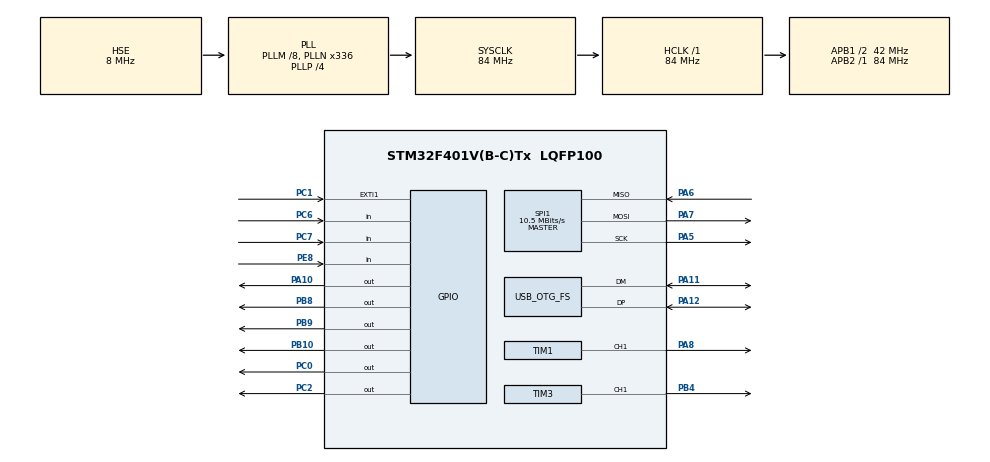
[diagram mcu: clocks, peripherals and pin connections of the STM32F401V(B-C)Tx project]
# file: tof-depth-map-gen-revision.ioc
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Dma.Request0=SPI1_RX
Dma.Request1=SPI1_TX
Dma.SPI1_RX.0.Direction=DMA_PERIPH_TO_MEMORY
Dma.SPI1_RX.0.FIFOMode=DMA_FIFOMODE_DISABLE
Dma.SPI1_RX.0.Instance=DMA2_Stream2
Dma.SPI1_RX.0.MemDataAlignment=DMA_MDATAALIGN_BYTE
Dma.SPI1_RX.0.MemInc=DMA_MINC_ENABLE
Dma.SPI1_RX.0.Mode=DMA_NORMAL
Dma.SPI1_RX.0.PeriphDataAlignment=DMA_PDATAALIGN_BYTE
Dma.SPI1_RX.0.PeriphInc=DMA_PINC_DISABLE
Dma.SPI1_RX.0.Priority=DMA_PRIORITY_LOW
Dma.SPI1_TX.1.Direction=DMA_MEMORY_TO_PERIPH
Dma.SPI1_TX.1.FIFOMode=DMA_FIFOMODE_DISABLE
Dma.SPI1_TX.1.Instance=DMA2_Stream3
Dma.SPI1_TX.1.MemDataAlignment=DMA_MDATAALIGN_BYTE
Dma.SPI1_TX.1.MemInc=DMA_MINC_ENABLE
Dma.SPI1_TX.1.Mode=DMA_NORMAL
Dma.SPI1_TX.1.PeriphDataAlignment=DMA_PDATAALIGN_BYTE
Dma.SPI1_TX.1.PeriphInc=DMA_PINC_DISABLE
Dma.SPI1_TX.1.Priority=DMA_PRIORITY_LOW
Mcu.Family=STM32F4
Mcu.Name=STM32F401V(B-C)Tx
Mcu.Package=LQFP100
NVIC.DMA2_Stream2_IRQn=true\:1\:1\:true\:false\:true\:false\:true
NVIC.DMA2_Stream3_IRQn=true\:1\:1\:true\:false\:true\:false\:true
NVIC.EXTI1_IRQn=true\:1\:3\:true\:false\:true\:true\:true
NVIC.OTG_FS_IRQn=true\:1\:5\:true\:false\:true\:true\:true
NVIC.PriorityGroup=NVIC_PRIORITYGROUP_1
NVIC.TIM2_IRQn=true\:1\:0\:true\:false\:true\:true\:true
PA10.Signal=GPIO_Output
PA11.Mode=Device_Only
PA11.Signal=USB_OTG_FS_DM
PA12.Mode=Device_Only
PA12.Signal=USB_OTG_FS_DP
PA5.Mode=Full_Duplex_Master
PA5.Signal=SPI1_SCK
PA6.Mode=Full_Duplex_Master
PA6.Signal=SPI1_MISO
PA7.Mode=Full_Duplex_Master
PA7.Signal=SPI1_MOSI
PA8.Signal=S_TIM1_CH1
PB10.Signal=GPIO_Output
PB4.Signal=S_TIM3_CH1
PB8.Signal=GPIO_Output
PB9.Signal=GPIO_Output
PC0.GPIO_PuPd=GPIO_PULLUP
PC0.Signal=GPIO_Output
PC1.GPIO_ModeDefaultEXTI=GPIO_MODE_IT_FALLING
PC1.GPIO_PuPd=GPIO_PULLUP
PC1.Signal=GPXTI1
PC2.GPIO_PuPd=GPIO_PULLUP
PC2.Signal=GPIO_Output
PC6.GPIO_PuPd=GPIO_PULLUP
PC6.Signal=GPIO_Input
PC7.GPIO_PuPd=GPIO_PULLUP
PC7.Signal=GPIO_Input
PE8.GPIO_PuPd=GPIO_PULLDOWN
PE8.Signal=GPIO_Input
PH0\ -\ OSC_IN.Mode=HSE-External-Oscillator
PH0\ -\ OSC_IN.Signal=RCC_OSC_IN
PH1\ -\ OSC_OUT.Mode=HSE-External-Oscillator
PH1\ -\ OSC_OUT.Signal=RCC_OSC_OUT
ProjectManager.HeapSize=0x200
ProjectManager.StackSize=0x400
ProjectManager.TargetToolchain=Makefile
RCC.48MHZClocksFreq_Value=48000000
RCC.AHBFreq_Value=84000000
RCC.APB1CLKDivider=RCC_HCLK_DIV2
RCC.APB1Freq_Value=42000000
RCC.APB1TimFreq_Value=84000000
RCC.APB2Freq_Value=84000000
RCC.APB2TimFreq_Value=84000000
RCC.CortexFreq_Value=84000000
RCC.HCLKFreq_Value=84000000
RCC.HSE_VALUE=8000000
RCC.HSI_VALUE=16000000
RCC.LSE_VALUE=32768
RCC.PLLM=8
RCC.PLLN=336
RCC.PLLP=RCC_PLLP_DIV4
RCC.PLLQ=7
RCC.SYSCLKFreq_VALUE=84000000
RCC.SYSCLKSource=RCC_SYSCLKSOURCE_PLLCLK
RCC.VCOOutputFreq_Value=336000000
SH.S_TIM1_CH1.0=TIM1_CH1,PWM Generation1 CH1
SH.S_TIM3_CH1.0=TIM3_CH1,PWM Generation1 CH1
SPI1.BaudRatePrescaler=SPI_BAUDRATEPRESCALER_8
SPI1.CLKPhase=SPI_PHASE_2EDGE
SPI1.CLKPolarity=SPI_POLARITY_HIGH
SPI1.CalculateBaudRate=10.5 MBits/s
SPI1.Direction=SPI_DIRECTION_2LINES
SPI1.FirstBit=SPI_FIRSTBIT_MSB
SPI1.Mode=SPI_MODE_MASTER
SPI1.VirtualType=VM_MASTER
TIM1.Channel-PWM\ Generation1\ CH1=TIM_CHANNEL_1
TIM1.ClockDivision=TIM_CLOCKDIVISION_DIV2
TIM1.OCFastMode_PWM-PWM\ Generation1\ CH1=TIM_OCFAST_DISABLE
TIM1.OCPolarity_1=TIM_OCPOLARITY_LOW
TIM2.Channel-Output\ Compare1\ No\ Output=TIM_CHANNEL_1
TIM2.Period=999999999
TIM2.Prescaler=83
TIM2.TIM_MasterOutputTrigger=TIM_TRGO_RESET
TIM3.Channel-PWM\ Generation1\ CH1=TIM_CHANNEL_1
TIM3.OCFastMode_PWM-PWM\ Generation1\ CH1=TIM_OCFAST_DISABLE
TIM3.OCPolarity_1=TIM_OCPOLARITY_LOW
USB_DEVICE.APP_RX_DATA_SIZE=768
USB_DEVICE.APP_TX_DATA_SIZE=512
USB_DEVICE.CLASS_NAME_FS=CDC
USB_DEVICE.MANUFACTURER_STRING=SICONTROLE
USB_DEVICE.PID_CDC_FS=31158
USB_DEVICE.PRODUCT_STRING_CDC_FS=TOF MAPGEN
USB_DEVICE.VID=6080
USB_DEVICE.VirtualMode=Cdc
USB_DEVICE.VirtualModeFS=Cdc_FS
USB_OTG_FS.VirtualMode=Device_Only
VP_TIM1_VS_ClockSourceINT.Mode=Internal
VP_TIM2_VS_ClockSourceINT.Mode=Internal
VP_TIM2_VS_no_output1.Mode=Output Compare1 No Output
VP_TIM3_VS_ClockSourceINT.Mode=Internal
VP_USB_DEVICE_VS_USB_DEVICE_CDC_FS.Mode=CDC_FS
board=custom

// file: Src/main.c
/* USER CODE BEGIN Header */
/**
  ******************************************************************************
  * @file           : main.c
  * @brief          : Main program body
  ******************************************************************************
  * @attention
  *
  * <h2><center>&copy; Copyright (c) 2019 STMicroelectronics.
  * All rights reserved.</center></h2>
  *
  * This software component is licensed by ST under Ultimate Liberty license
  * SLA0044, the "License"; You may not use this file except in compliance with
  * the License. You may obtain a copy of the License at:
  *                             www.st.com/SLA0044
  *
  ******************************************************************************
  */
/* USER CODE END Header */

#include "main.h"
#include "usb_device.h"

SPI_HandleTypeDef hspi1;
DMA_HandleTypeDef hdma_spi1_rx;
DMA_HandleTypeDef hdma_spi1_tx;

TIM_HandleTypeDef htim1;
TIM_HandleTypeDef htim2;
TIM_HandleTypeDef htim3;

void SystemClock_Config(void);
static void MX_GPIO_Init(void);
static void MX_DMA_Init(void);
static void MX_SPI1_Init(void);
static void MX_TIM1_Init(void);
static void MX_TIM2_Init(void);
static void MX_TIM3_Init(void);

int main(void)
{

  /* MCU Configuration--------------------------------------------------------*/

  /* Reset of all peripherals, Initializes the Flash interface and the Systick. */
  HAL_Init();

  /* Configure the system clock */
  SystemClock_Config();

  /* Initialize all configured peripherals */
  MX_GPIO_Init();
  MX_DMA_Init();
  MX_SPI1_Init();
  MX_TIM1_Init();
  MX_USB_DEVICE_Init();
  MX_TIM2_Init();
  MX_TIM3_Init();
  /* USER CODE BEGIN 2 */
    // Init NVIC

  /* USER CODE END 2 */

  /* Infinite loop */
  /* USER CODE BEGIN WHILE */
    void appMain();
    appMain();

    // Program will not pass this segment.
    while ( 1 ) {
    /* USER CODE END WHILE */

    }
}

void SystemClock_Config(void)
{
  RCC_OscInitTypeDef RCC_OscInitStruct = {0};
  RCC_ClkInitTypeDef RCC_ClkInitStruct = {0};

  /** Configure the main internal regulator output voltage
  */
  __HAL_RCC_PWR_CLK_ENABLE();
  __HAL_PWR_VOLTAGESCALING_CONFIG(PWR_REGULATOR_VOLTAGE_SCALE2);
  /** Initializes the CPU, AHB and APB busses clocks
  */
  RCC_OscInitStruct.OscillatorType = RCC_OSCILLATORTYPE_HSE;
  RCC_OscInitStruct.HSEState = RCC_HSE_ON;
  RCC_OscInitStruct.PLL.PLLState = RCC_PLL_ON;
  RCC_OscInitStruct.PLL.PLLSource = RCC_PLLSOURCE_HSE;
  RCC_OscInitStruct.PLL.PLLM = 8;
  RCC_OscInitStruct.PLL.PLLN = 336;
  RCC_OscInitStruct.PLL.PLLP = RCC_PLLP_DIV4;
  RCC_OscInitStruct.PLL.PLLQ = 7;
  if (HAL_RCC_OscConfig(&RCC_OscInitStruct) != HAL_OK)
  {
    Error_Handler();
  }
  /** Initializes the CPU, AHB and APB busses clocks
  */
  RCC_ClkInitStruct.ClockType = RCC_CLOCKTYPE_HCLK|RCC_CLOCKTYPE_SYSCLK
                              |RCC_CLOCKTYPE_PCLK1|RCC_CLOCKTYPE_PCLK2;
  RCC_ClkInitStruct.SYSCLKSource = RCC_SYSCLKSOURCE_PLLCLK;
  RCC_ClkInitStruct.AHBCLKDivider = RCC_SYSCLK_DIV1;
  RCC_ClkInitStruct.APB1CLKDivider = RCC_HCLK_DIV2;
  RCC_ClkInitStruct.APB2CLKDivider = RCC_HCLK_DIV1;

  if (HAL_RCC_ClockConfig(&RCC_ClkInitStruct, FLASH_LATENCY_2) != HAL_OK)
  {
    Error_Handler();
  }
}

static void MX_SPI1_Init(void)
{

  /* SPI1 parameter configuration*/
  hspi1.Instance = SPI1;
  hspi1.Init.Mode = SPI_MODE_MASTER;
  hspi1.Init.Direction = SPI_DIRECTION_2LINES;
  hspi1.Init.DataSize = SPI_DATASIZE_8BIT;
  hspi1.Init.CLKPolarity = SPI_POLARITY_HIGH;
  hspi1.Init.CLKPhase = SPI_PHASE_2EDGE;
  hspi1.Init.NSS = SPI_NSS_SOFT;
  hspi1.Init.BaudRatePrescaler = SPI_BAUDRATEPRESCALER_8;
  hspi1.Init.FirstBit = SPI_FIRSTBIT_MSB;
  hspi1.Init.TIMode = SPI_TIMODE_DISABLE;
  hspi1.Init.CRCCalculation = SPI_CRCCALCULATION_DISABLE;
  hspi1.Init.CRCPolynomial = 10;
  if (HAL_SPI_Init(&hspi1) != HAL_OK)
  {
    Error_Handler();
  }

}

static void MX_TIM1_Init(void)
{

  TIM_ClockConfigTypeDef sClockSourceConfig = {0};
  TIM_MasterConfigTypeDef sMasterConfig = {0};
  TIM_OC_InitTypeDef sConfigOC = {0};
  TIM_BreakDeadTimeConfigTypeDef sBreakDeadTimeConfig = {0};

  htim1.Instance = TIM1;
  htim1.Init.Prescaler = 0;
  htim1.Init.CounterMode = TIM_COUNTERMODE_UP;
  htim1.Init.Period = 0;
  htim1.Init.ClockDivision = TIM_CLOCKDIVISION_DIV2;
  htim1.Init.RepetitionCounter = 0;
  htim1.Init.AutoReloadPreload = TIM_AUTORELOAD_PRELOAD_DISABLE;
  if (HAL_TIM_Base_Init(&htim1) != HAL_OK)
  {
    Error_Handler();
  }
  sClockSourceConfig.ClockSource = TIM_CLOCKSOURCE_INTERNAL;
  if (HAL_TIM_ConfigClockSource(&htim1, &sClockSourceConfig) != HAL_OK)
  {
    Error_Handler();
  }
  if (HAL_TIM_PWM_Init(&htim1) != HAL_OK)
  {
    Error_Handler();
  }
  sMasterConfig.MasterOutputTrigger = TIM_TRGO_RESET;
  sMasterConfig.MasterSlaveMode = TIM_MASTERSLAVEMODE_DISABLE;
  if (HAL_TIMEx_MasterConfigSynchronization(&htim1, &sMasterConfig) != HAL_OK)
  {
    Error_Handler();
  }
  sConfigOC.OCMode = TIM_OCMODE_PWM1;
  sConfigOC.Pulse = 0;
  sConfigOC.OCPolarity = TIM_OCPOLARITY_LOW;
  sConfigOC.OCNPolarity = TIM_OCNPOLARITY_HIGH;
  sConfigOC.OCFastMode = TIM_OCFAST_DISABLE;
  sConfigOC.OCIdleState = TIM_OCIDLESTATE_RESET;
  sConfigOC.OCNIdleState = TIM_OCNIDLESTATE_RESET;
  if (HAL_TIM_PWM_ConfigChannel(&htim1, &sConfigOC, TIM_CHANNEL_1) != HAL_OK)
  {
    Error_Handler();
  }
  sBreakDeadTimeConfig.OffStateRunMode = TIM_OSSR_DISABLE;
  sBreakDeadTimeConfig.OffStateIDLEMode = TIM_OSSI_DISABLE;
  sBreakDeadTimeConfig.LockLevel = TIM_LOCKLEVEL_OFF;
  sBreakDeadTimeConfig.DeadTime = 0;
  sBreakDeadTimeConfig.BreakState = TIM_BREAK_DISABLE;
  sBreakDeadTimeConfig.BreakPolarity = TIM_BREAKPOLARITY_HIGH;
  sBreakDeadTimeConfig.AutomaticOutput = TIM_AUTOMATICOUTPUT_DISABLE;
  if (HAL_TIMEx_ConfigBreakDeadTime(&htim1, &sBreakDeadTimeConfig) != HAL_OK)
  {
    Error_Handler();
  }
  HAL_TIM_MspPostInit(&htim1);

}

static void MX_TIM2_Init(void)
{

  TIM_ClockConfigTypeDef sClockSourceConfig = {0};
  TIM_MasterConfigTypeDef sMasterConfig = {0};
  TIM_OC_InitTypeDef sConfigOC = {0};

  htim2.Instance = TIM2;
  htim2.Init.Prescaler = 83;
  htim2.Init.CounterMode = TIM_COUNTERMODE_UP;
  htim2.Init.Period = 999999999;
  htim2.Init.ClockDivision = TIM_CLOCKDIVISION_DIV1;
  htim2.Init.AutoReloadPreload = TIM_AUTORELOAD_PRELOAD_DISABLE;
  if (HAL_TIM_Base_Init(&htim2) != HAL_OK)
  {
    Error_Handler();
  }
  sClockSourceConfig.ClockSource = TIM_CLOCKSOURCE_INTERNAL;
  if (HAL_TIM_ConfigClockSource(&htim2, &sClockSourceConfig) != HAL_OK)
  {
    Error_Handler();
  }
  if (HAL_TIM_OC_Init(&htim2) != HAL_OK)
  {
    Error_Handler();
  }
  sMasterConfig.MasterOutputTrigger = TIM_TRGO_RESET;
  sMasterConfig.MasterSlaveMode = TIM_MASTERSLAVEMODE_DISABLE;
  if (HAL_TIMEx_MasterConfigSynchronization(&htim2, &sMasterConfig) != HAL_OK)
  {
    Error_Handler();
  }
  sConfigOC.OCMode = TIM_OCMODE_TIMING;
  sConfigOC.Pulse = 0;
  sConfigOC.OCPolarity = TIM_OCPOLARITY_HIGH;
  sConfigOC.OCFastMode = TIM_OCFAST_DISABLE;
  if (HAL_TIM_OC_ConfigChannel(&htim2, &sConfigOC, TIM_CHANNEL_1) != HAL_OK)
  {
    Error_Handler();
  }
  /* USER CODE BEGIN TIM2_Init 2 */
  __HAL_TIM_CLEAR_FLAG(&htim2, TIM_FLAG_UPDATE);
    HAL_TIM_Base_Start_IT( &htim2 );
  /* USER CODE END TIM2_Init 2 */

}

static void MX_TIM3_Init(void)
{

  TIM_ClockConfigTypeDef sClockSourceConfig = {0};
  TIM_MasterConfigTypeDef sMasterConfig = {0};
  TIM_OC_InitTypeDef sConfigOC = {0};

  htim3.Instance = TIM3;
  htim3.Init.Prescaler = 0;
  htim3.Init.CounterMode = TIM_COUNTERMODE_UP;
  htim3.Init.Period = 0;
  htim3.Init.ClockDivision = TIM_CLOCKDIVISION_DIV1;
  htim3.Init.AutoReloadPreload = TIM_AUTORELOAD_PRELOAD_DISABLE;
  if (HAL_TIM_Base_Init(&htim3) != HAL_OK)
  {
    Error_Handler();
  }
  sClockSourceConfig.ClockSource = TIM_CLOCKSOURCE_INTERNAL;
  if (HAL_TIM_ConfigClockSource(&htim3, &sClockSourceConfig) != HAL_OK)
  {
    Error_Handler();
  }
  if (HAL_TIM_PWM_Init(&htim3) != HAL_OK)
  {
    Error_Handler();
  }
  sMasterConfig.MasterOutputTrigger = TIM_TRGO_RESET;
  sMasterConfig.MasterSlaveMode = TIM_MASTERSLAVEMODE_DISABLE;
  if (HAL_TIMEx_MasterConfigSynchronization(&htim3, &sMasterConfig) != HAL_OK)
  {
    Error_Handler();
  }
  sConfigOC.OCMode = TIM_OCMODE_PWM1;
  sConfigOC.Pulse = 0;
  sConfigOC.OCPolarity = TIM_OCPOLARITY_LOW;
  sConfigOC.OCFastMode = TIM_OCFAST_DISABLE;
  if (HAL_TIM_PWM_ConfigChannel(&htim3, &sConfigOC, TIM_CHANNEL_1) != HAL_OK)
  {
    Error_Handler();
  }
  HAL_TIM_MspPostInit(&htim3);

}

static void MX_DMA_Init(void)
{

  /* DMA controller clock enable */
  __HAL_RCC_DMA2_CLK_ENABLE();

  /* DMA interrupt init */
  /* DMA2_Stream2_IRQn interrupt configuration */
  HAL_NVIC_SetPriority(DMA2_Stream2_IRQn, 1, 1);
  HAL_NVIC_EnableIRQ(DMA2_Stream2_IRQn);
  /* DMA2_Stream3_IRQn interrupt configuration */
  HAL_NVIC_SetPriority(DMA2_Stream3_IRQn, 1, 1);
  HAL_NVIC_EnableIRQ(DMA2_Stream3_IRQn);

}

static void MX_GPIO_Init(void)
{
  GPIO_InitTypeDef GPIO_InitStruct = {0};

  /* GPIO Ports Clock Enable */
  __HAL_RCC_GPIOH_CLK_ENABLE();
  __HAL_RCC_GPIOC_CLK_ENABLE();
  __HAL_RCC_GPIOA_CLK_ENABLE();
  __HAL_RCC_GPIOE_CLK_ENABLE();
  __HAL_RCC_GPIOB_CLK_ENABLE();

  /*Configure GPIO pin Output Level */
  HAL_GPIO_WritePin(GPIOC, GPIO_PIN_0|GPIO_PIN_2, GPIO_PIN_RESET);

  /*Configure GPIO pin Output Level */
  HAL_GPIO_WritePin(GPIOB, GPIO_PIN_10|GPIO_PIN_8|GPIO_PIN_9, GPIO_PIN_RESET);

  /*Configure GPIO pin Output Level */
  HAL_GPIO_WritePin(GPIOA, GPIO_PIN_10, GPIO_PIN_RESET);

  /*Configure GPIO pins : PC0 PC2 */
  GPIO_InitStruct.Pin = GPIO_PIN_0|GPIO_PIN_2;
  GPIO_InitStruct.Mode = GPIO_MODE_OUTPUT_PP;
  GPIO_InitStruct.Pull = GPIO_PULLUP;
  GPIO_InitStruct.Speed = GPIO_SPEED_FREQ_LOW;
  HAL_GPIO_Init(GPIOC, &GPIO_InitStruct);

  /*Configure GPIO pin : PC1 */
  GPIO_InitStruct.Pin = GPIO_PIN_1;
  GPIO_InitStruct.Mode = GPIO_MODE_IT_FALLING;
  GPIO_InitStruct.Pull = GPIO_PULLUP;
  HAL_GPIO_Init(GPIOC, &GPIO_InitStruct);

  /*Configure GPIO pin : PE8 */
  GPIO_InitStruct.Pin = GPIO_PIN_8;
  GPIO_InitStruct.Mode = GPIO_MODE_INPUT;
  GPIO_InitStruct.Pull = GPIO_PULLDOWN;
  HAL_GPIO_Init(GPIOE, &GPIO_InitStruct);

  /*Configure GPIO pins : PB10 PB8 PB9 */
  GPIO_InitStruct.Pin = GPIO_PIN_10|GPIO_PIN_8|GPIO_PIN_9;
  GPIO_InitStruct.Mode = GPIO_MODE_OUTPUT_PP;
  GPIO_InitStruct.Pull = GPIO_NOPULL;
  GPIO_InitStruct.Speed = GPIO_SPEED_FREQ_LOW;
  HAL_GPIO_Init(GPIOB, &GPIO_InitStruct);

  /*Configure GPIO pins : PC6 PC7 */
  GPIO_InitStruct.Pin = GPIO_PIN_6|GPIO_PIN_7;
  GPIO_InitStruct.Mode = GPIO_MODE_INPUT;
  GPIO_InitStruct.Pull = GPIO_PULLUP;
  HAL_GPIO_Init(GPIOC, &GPIO_InitStruct);

  /*Configure GPIO pin : PA10 */
  GPIO_InitStruct.Pin = GPIO_PIN_10;
  GPIO_InitStruct.Mode = GPIO_MODE_OUTPUT_PP;
  GPIO_InitStruct.Pull = GPIO_NOPULL;
  GPIO_InitStruct.Speed = GPIO_SPEED_FREQ_LOW;
  HAL_GPIO_Init(GPIOA, &GPIO_InitStruct);

  /* EXTI interrupt init*/
  HAL_NVIC_SetPriority(EXTI1_IRQn, 1, 3);
  HAL_NVIC_EnableIRQ(EXTI1_IRQn);

}

void Error_Handler(void)
{
  /* USER CODE BEGIN Error_Handler_Debug */
    /* User can add his own implementation to report the HAL error return state */
    while ( 1 )
        ;
  /* USER CODE END Error_Handler_Debug */
}

/************************ (C) COPYRIGHT STMicroelectronics *****END OF FILE****/
